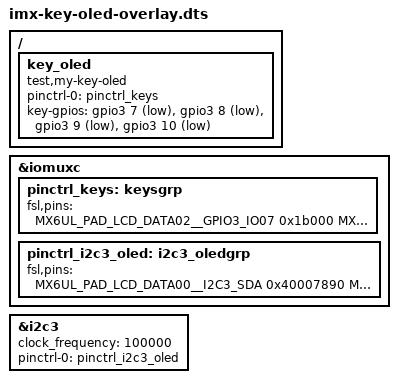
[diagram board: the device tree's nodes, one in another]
/*
 * Copyright (C) 2024
 * filename : imx-key-oled-overlay.dts
 * brief    : 自定义四按键 + 0.96寸OLED 设备树插件
 * author   : martinx
 * date     : 2024-06-04
 *
 * ================================================================
 * 硬件连线一览
 * ================================================================
 * ┌─────────┬───────────────────────┬──────────┬─────────────────┐
 * │  功能   │ 引脚宏（ALT模式）      │ GPIO     │ 开发板位置       │
 * ├─────────┼───────────────────────┼──────────┼─────────────────┤
 * │ K1 按键 │ LCD_DATA02__GPIO3_IO07 │ GPIO3_7  │ P31 (按下→GND)  │
 * │ K2 按键 │ LCD_DATA03__GPIO3_IO08 │ GPIO3_8  │ P30 (按下→GND)  │
 * │ K3 按键 │ LCD_DATA04__GPIO3_IO09 │ GPIO3_9  │ P29 (按下→GND)  │
 * │ K4 按键 │ LCD_DATA05__GPIO3_IO10 │ GPIO3_10 │ P28 (按下→GND)  │
 * │ I2C3 SDA│ LCD_DATA00__I2C3_SDA   │ —        │ OLED SSD1306    │
 * │ I2C3 SCL│ LCD_DATA01__I2C3_SCL   │ —        │ OLED SSD1306    │
 * └─────────┴───────────────────────┴──────────┴─────────────────┘
 *
 * ================================================================
 * overlay 叠加关系（关键!）
 * ================================================================
 * 本 overlay 自包含 I2C3 配置, 不依赖 imx-fire-i2c3.dtbo。
 * uEnv.txt 只需一行: load_overlay=imx-key-oled.dtbo
 *
 * I2C 引脚电气属性 0x40007890 对齐裸机已验证的 PAD_CTL_I2C_OD:
 *   ODE=1(开漏) DSE=2(R0/4) SPEED=2(100MHz) PKE=1 PUE=1 PUS=1(47K) SION=1
 *
 * ================================================================
 * 设备树节点层次（叠加后）
 * ================================================================
 * / {
 *     key_oled {                          ← 本 overlay fragment@0
 *         compatible = "test,my-key-oled";
 *         pinctrl-0 = <&pinctrl_keys>;
 *         key-gpios = <4个>;
 *     };
 * };
 *
 * &i2c3 {                                 ← 由 imx-fire-i2c3.dtbo 使能
 *     clock_frequency = <100000>;
 *     pinctrl-0 = <&pinctrl_i2c3>;
 *     status = "okay";
 * };
 *
 * &iomuxc {
 *     pinctrl_keys { ... };               ← 本 overlay fragment@1
 *     pinctrl_i2c3 { ... };               ← 由 imx-fire-i2c3.dtbo 提供
 * };
 * ================================================================
 */

/dts-v1/;
/plugin/;

#include "../imx6ul-pinfunc.h"
#include "dt-bindings/gpio/gpio.h"

/{

	/* ============================================================
	 * fragment@0: 在根节点 "/" 下插入 "key_oled" 平台设备节点
	 * ============================================================
	 * 一个 compatible 管理 4 个按键 GPIO。I2C3 总线由野火
	 * imx-fire-i2c3.dtbo 使能，驱动中通过 i2c_get_adapter(3) 获取。
	 */
	fragment@0 {
		target-path = "/";
		__overlay__ {

			/* ─── 按键+OLED 平台设备 ───────────────────────── */
			key_oled {
				/*
				 * 驱动中 of_match_table 必须包含此字符串:
				 *   { .compatible = "test,my-key-oled" }
				 */
				compatible = "test,my-key-oled";

				/* pinctrl 只管理按键引脚 */
				pinctrl-names = "default";
				pinctrl-0 = <&pinctrl_keys>;

				/*
				 * key-gpios: 四个按键 GPIO（数组形式）
				 *
				 * 驱动中用 devm_gpiod_get_index() 按 index 获取:
				 *   index=0 → GPIO3_IO07 (K1)
				 *   index=1 → GPIO3_IO08 (K2)
				 *   index=2 → GPIO3_IO09 (K3)
				 *   index=3 → GPIO3_IO10 (K4)
				 *
				 * GPIO_ACTIVE_LOW:
				 *   K 按下 → GND(低电平) → gpiod_get_value() 返回 1
				 *   K 松开 → 上拉(高电平) → gpiod_get_value() 返回 0
				 */
				key-gpios = <&gpio3 7  GPIO_ACTIVE_LOW>,   /* K1 */
				            <&gpio3 8  GPIO_ACTIVE_LOW>,   /* K2 */
				            <&gpio3 9  GPIO_ACTIVE_LOW>,   /* K3 */
				            <&gpio3 10 GPIO_ACTIVE_LOW>;   /* K4 */
			};
		};
	};

	/* ============================================================
	 * fragment@1: 4 个按键 GPIO 的 IOMUXC 电气属性配置
	 * ============================================================
	 * I2C3 引脚（LCD_DATA00/01）的 pinctrl 由野火
	 * imx-fire-i2c3.dtbo 中的 pinctrl_i2c3 节点提供,
	 * 本 overlay 不重复配置。
	 */
	fragment@1 {
		target = <&iomuxc>;
		__overlay__ {

			/* ─── 4 个按键 GPIO 引脚配置 ────────────────────────
			 *
			 * 4 个按键共用电容属性 0x1b000:
			 *
			 * 0x0001b000 = 0b 0000 0000 0000 0001 1011 0000 0000 0000
			 *
			 * BIT  | 字段  | 值 | 含义
			 * ─────|───────|────|───────────────────────────────
			 *  0   | SRE   | 0  | 慢速压摆率 (按键信号变化极慢)
			 *  3-5 | DSE   |000 | 输出驱动关闭 (纯输入引脚)
			 *  6-7 | SPEED |00  | 50MHz 带宽 (按键 ≤ Hz 级)
			 * 11   | ODE   | 0  | 非开漏 (与输入模式无关)
			 * 12   | PKE   | 1  | 使能内部上拉/保持器
			 * 13   | PUE   | 1  | 选择上拉 (而非保持器)
			 * 14-15| PUS   |10  | 100KΩ 上拉电阻
			 * 16   | HYS   | 1  | 施密特触发器使能 (硬件消抖)
			 *
			 * 上拉原理:
			 *   常态 → 100KΩ 上拉到 3.3V → 引脚读"1"(高)
			 *   K按下 → GND 短路到地     → 引脚读"0"(低)
			 */
			pinctrl_keys: keysgrp {
				fsl,pins = <
					/* K1: LCD_DATA02 ALT5 → GPIO3_IO07 */
					MX6UL_PAD_LCD_DATA02__GPIO3_IO07  0x1b000
					/* K2: LCD_DATA03 ALT5 → GPIO3_IO08 */
					MX6UL_PAD_LCD_DATA03__GPIO3_IO08  0x1b000
					/* K3: LCD_DATA04 ALT5 → GPIO3_IO09 */
					MX6UL_PAD_LCD_DATA04__GPIO3_IO09  0x1b000
					/* K4: LCD_DATA05 ALT5 → GPIO3_IO10 */
					MX6UL_PAD_LCD_DATA05__GPIO3_IO10  0x1b000
				>;
			};

			/* ─── I2C3 引脚配置 (对齐裸机工作值) ────────
				*
				* 裸机 PAD_CTL_I2C_OD 对应值 0x40007890:
				*
				* 0x40007890 = 0b 0100 0000 0000 0000 0111 1000 1001 0000
				*
				* BIT  | 字段  | 值 | 含义
				* ─────|───────|────|───────────────────────────────
				*  0   | SRE   | 0  | 慢速压摆率
				*  3-5 | DSE   |010 | 驱动强度 R0/4
				*  6-7 | SPEED |10  | 100MHz 带宽
				* 11   | ODE   | 1  | 开漏使能 (I2C 必需)
				* 12   | PKE   | 1  | 使能上拉/保持器
				* 13   | PUE   | 1  | 上拉使能
				* 14-15| PUS   |01  | 47KΩ 上拉 (裸机验证值)
				* 16   | HYS   | 0  | 无迟滞 (I2C 不需要)
				* 30   | SION  | 1  | 强制使能输入通路
				*/
			pinctrl_i2c3_oled: i2c3_oledgrp {
				fsl,pins = <
					MX6UL_PAD_LCD_DATA00__I2C3_SDA  0x40007890
					MX6UL_PAD_LCD_DATA01__I2C3_SCL  0x40007890
				>;
			};
		};
	};

	/* ============================================================
	 * fragment@2: 使能 I2C3 控制器, 使用裸机验证的 PAD_CTL
	 * ============================================================ */
	fragment@2 {
		target = <&i2c3>;
		__overlay__ {
			clock_frequency = <100000>;
			pinctrl-names = "default";
			pinctrl-0 = <&pinctrl_i2c3_oled>;
			status = "okay";
		};
	};
};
